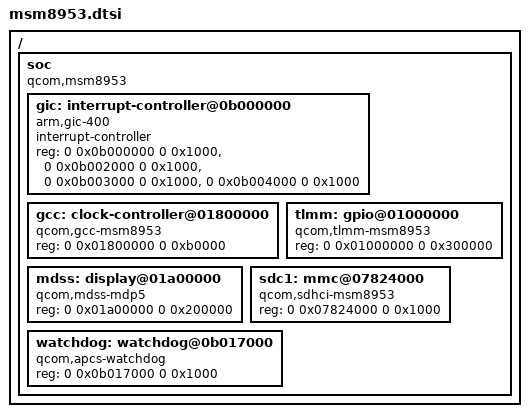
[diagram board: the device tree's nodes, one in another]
/dts-v1/;
/plugin/;

/ {
	// Qualcomm MSM8953 / Snapdragon 632 shared platform resources.
	// Memory map per edk2-msm Documentation/devices/onclite.md:
	//   Bank 0 (Low RAM):  0x40000000 - 0x80000000  (1 GiB)
	//   Bank 1 (High RAM): 0x80000000 - 0x100000000 (2 GiB)
	//   UEFI FD:           0x9C000000 - 0x9E000000  (32 MiB)
	//   Framebuffer:       0x90000000 - 0x90800000  (8 MiB)
	//   ABOOT tags/FDT:    0x43400000 - 0x43600000  (2 MiB)
	soc {
		compatible = "qcom,msm8953";
		#address-cells = <2>;
		#size-cells = <2>;
		ranges;

		gic: interrupt-controller@0b000000 {
			compatible = "arm,gic-400", "arm,cortex-a15-gic";
			#interrupt-cells = <3>;
			interrupt-controller;
			reg = <0 0x0b000000 0 0x1000>,
			      <0 0x0b002000 0 0x1000>,
			      <0 0x0b003000 0 0x1000>,
			      <0 0x0b004000 0 0x1000>;
		};

		gcc: clock-controller@01800000 {
			compatible = "qcom,gcc-msm8953";
			reg = <0 0x01800000 0 0xb0000>;
		};

		tlmm: gpio@01000000 {
			compatible = "qcom,tlmm-msm8953";
			reg = <0 0x01000000 0 0x300000>;
		};

		mdss: display@01a00000 {
			compatible = "qcom,mdss-mdp5";
			reg = <0 0x01a00000 0 0x200000>;
		};

		sdc1: mmc@07824000 {
			compatible = "qcom,sdhci-msm8953";
			reg = <0 0x07824000 0 0x1000>;
		};

		watchdog: watchdog@0b017000 {
			compatible = "qcom,apcs-watchdog";
			reg = <0 0x0b017000 0 0x1000>;
		};
	};
};
